# LargeDummyDevice register map
File version: 1.0
Registers are 32-bit, read-write, no defined reset value unless marked. A register's access mark holds for its fields unless they carry their own. Offsets are from the block's base; [hi:lo] are bit positions.

## PERIPHERAL_41
Base 0x40028000
0x04 REG_1 — Register 1
  [35:31] FIELD_29, [32:30] FIELD_13, [32:29] FIELD_31, [29:28] FIELD_12, [29:28] FIELD_23, [31:27] FIELD_22, [26:25] FIELD_4, [28:25] FIELD_28, [27:23] FIELD_15, [22] FIELD_21, [24:21] FIELD_6, [23:21] FIELD_10, [21] FIELD_25, [18:16] FIELD_5, [16] FIELD_8, [17:16] FIELD_9, [18:16] FIELD_16, [19:15] FIELD_1, [16:14] FIELD_7, [16:13] FIELD_3, [15:13] FIELD_18, [14:13] FIELD_20, [13] FIELD_24, [16:12] FIELD_14, [13:12] FIELD_17, [9:8] FIELD_26, [9:8] FIELD_30, [11:8] FIELD_32, [6:3] FIELD_2, [5:3] FIELD_19, [4:0] FIELD_11, [4:0] FIELD_27

## PERIPHERAL_48
Base 0x4002F000
0x04 REG_1 — Register 1
  [34:30] FIELD_16, [30:28] FIELD_18, [29:27] FIELD_12, [31:27] FIELD_20, [27:26] FIELD_28, [24] FIELD_27, [24:23] FIELD_24, [24:22] FIELD_6, [26:22] FIELD_19, [23:21] FIELD_4, [20] FIELD_3, [22:20] FIELD_13, [19:17] FIELD_7, [20:17] FIELD_14, [19:17] FIELD_15, [20:16] FIELD_21, [16:13] FIELD_10, [17:13] FIELD_11, [15:12] FIELD_25, [15:11] FIELD_2, [12:11] FIELD_22, [13:11] FIELD_23, [12:9] FIELD_17, [10:8] FIELD_26, [6:3] FIELD_1, [6:2] FIELD_8, [5:1] FIELD_5, [5:1] FIELD_9

## PERIPHERAL_52
Base 0x40033000
0x04 REG_1 — Register 1
  [33:30] FIELD_8, [33:29] FIELD_6, [33:29] FIELD_19, [32:28] FIELD_12, [27:24] FIELD_20, [26:23] FIELD_14, [25:22] FIELD_5, [25:22] FIELD_13, [23:22] FIELD_15, [24:20] FIELD_3, [19:17] FIELD_11, [16] FIELD_9, [18:15] FIELD_7, [16:12] FIELD_4, [12] FIELD_18, [13:9] FIELD_17, [12:8] FIELD_1, [8] FIELD_16, [5] FIELD_21, [8:4] FIELD_2, [4:1] FIELD_10
0x08 REG_2 — Register 2
  [31] FIELD_12, [34:31] FIELD_16, [32:29] FIELD_10, [29:28] FIELD_3, [27:23] FIELD_13, [25:23] FIELD_15, [23:19] FIELD_9, [22:18] FIELD_19, [19:15] FIELD_2, [14:12] FIELD_5, [13:12] FIELD_14, [10] FIELD_17, [10:9] FIELD_18, [11:7] FIELD_8, [6] FIELD_1, [5] FIELD_11, [2] FIELD_7, [1] FIELD_6, [0] FIELD_4
0x0C REG_3 — Register 3
  [33:31] FIELD_8, [35:31] FIELD_17, [31:30] FIELD_14, [27] FIELD_18, [28:26] FIELD_19, [24] FIELD_21, [26:22] FIELD_26, [21] FIELD_7, [23:21] FIELD_16, [19] FIELD_22, [21:18] FIELD_20, [16:15] FIELD_9, [17:15] FIELD_11, [18:14] FIELD_24, [13] FIELD_15, [13:12] FIELD_3, [12] FIELD_23, [10] FIELD_5, [11:8] FIELD_10, [8] FIELD_12, [10:8] FIELD_13, [8:5] FIELD_4, [3:2] FIELD_1, [2] FIELD_2, [4:1] FIELD_6, [0] FIELD_25
0x10 REG_4 — Register 4
  [8:7] FIELD_1
0x14 REG_5 — Register 5
  [32:31] FIELD_6, [33:30] FIELD_9, [28] FIELD_12, [31:27] FIELD_1, [28:26] FIELD_4, [25:23] FIELD_11, [23:20] FIELD_3, [14] FIELD_10, [17:14] FIELD_14, [16:14] FIELD_15, [12:10] FIELD_2, [13:9] FIELD_13, [4] FIELD_5, [5:2] FIELD_8, [1] FIELD_7

## PERIPHERAL_55
Base 0x40036000
0x04 REG_1 — Register 1
  [32:31] FIELD_7, [30] FIELD_9, [29:25] FIELD_2, [26:22] FIELD_3, [22] FIELD_11, [22:19] FIELD_6, [18:15] FIELD_4, [10:7] FIELD_5, [6:3] FIELD_1, [4:3] FIELD_8, [3:1] FIELD_10
0x08 REG_2 — Register 2
  [30:26] FIELD_9, [26] FIELD_22, [28:25] FIELD_4, [28:24] FIELD_18, [24:22] FIELD_1, [24:21] FIELD_5, [21:20] FIELD_11, [24:20] FIELD_20, [20] FIELD_23, [22:19] FIELD_13, [23:19] FIELD_19, [23:19] FIELD_25, [18] FIELD_14, [18:15] FIELD_16, [16:12] FIELD_12, [8] FIELD_7, [9:7] FIELD_15, [7:6] FIELD_2, [7:5] FIELD_3, [7:3] FIELD_6, [6:3] FIELD_21, [4:3] FIELD_24, [3:2] FIELD_17, [1] FIELD_8, [2:0] FIELD_10
0x0C REG_3 — Register 3
  [11:7] FIELD_1
0x10 REG_4 — Register 4
  [31:28] FIELD_7, [29:27] FIELD_10, [26] FIELD_11, [27:23] FIELD_5, [20] FIELD_3, [19] FIELD_8, [15:11] FIELD_6, [8:5] FIELD_2, [5:4] FIELD_9, [7:3] FIELD_1, [1] FIELD_4
0x14 REG_5 — Register 5
  [30] FIELD_3, [28:24] FIELD_2, [20:18] FIELD_4, [18:17] FIELD_5, [11:7] FIELD_1
0x18 REG_6 — Register 6
  [34:31] FIELD_4, [30] FIELD_5, [30:29] FIELD_6, [29:28] FIELD_7, [27] FIELD_1, [25:22] FIELD_3, [16:13] FIELD_2, [12:10] FIELD_9, [4:1] FIELD_8
0x1C REG_7 — Register 7
  [31] FIELD_1, [34:31] FIELD_3, [32:31] FIELD_13, [27:23] FIELD_6, [25:23] FIELD_18, [22:21] FIELD_22, [24:20] FIELD_2, [24:20] FIELD_14, [19] FIELD_5, [19:16] FIELD_7, [16:13] FIELD_11, [16:12] FIELD_9, [14:11] FIELD_10, [10:9] FIELD_17, [6:5] FIELD_12, [8:5] FIELD_16, [4:3] FIELD_20, [2] FIELD_15, [4:2] FIELD_19, [1] FIELD_8, [4:1] FIELD_21, [4:0] FIELD_4
0x20 REG_8 — Register 8
  [31:27] FIELD_18, [28:25] FIELD_3, [24:22] FIELD_17, [22:21] FIELD_16, [20:18] FIELD_10, [18] FIELD_11, [19:18] FIELD_14, [21:17] FIELD_12, [17:16] FIELD_7, [17:14] FIELD_8, [12] FIELD_1, [16:12] FIELD_4, [9] FIELD_6, [8:6] FIELD_9, [6:5] FIELD_15, [9:5] FIELD_19, [7:3] FIELD_5, [4:2] FIELD_2, [4:1] FIELD_13
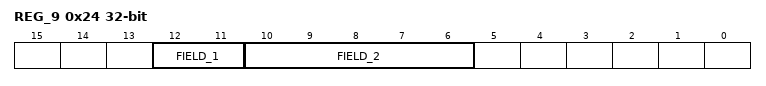
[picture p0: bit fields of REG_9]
0x24 REG_9 — Register 9
  [12:11] FIELD_1, [10:6] FIELD_2
0x28 REG_10 — Register 10
  [32:29] FIELD_15, [28] FIELD_1, [27] FIELD_5, [25:22] FIELD_3, [19] FIELD_9, [16:15] FIELD_8, [17:14] FIELD_14, [16:12] FIELD_2, [13:9] FIELD_6, [13:9] FIELD_16, [9:8] FIELD_10, [6:3] FIELD_4, [4:3] FIELD_11, [4:3] FIELD_13, [2:1] FIELD_12, [2:0] FIELD_7
0x2C REG_11 — Register 11
  [32:31] FIELD_2, [32:31] FIELD_15, [31:30] FIELD_12, [32:30] FIELD_21, [31:28] FIELD_13, [28] FIELD_27, [27] FIELD_9, [27] FIELD_11, [31:27] FIELD_16, [27] FIELD_18, [28:26] FIELD_17, [25] FIELD_8, [25:24] FIELD_7, [25:24] FIELD_23, [23:21] FIELD_14, [18] FIELD_30, [21:17] FIELD_5, [21:17] FIELD_26, [21:17] FIELD_31, [16] FIELD_19, [17:13] FIELD_10, [16:13] FIELD_20, [14:13] FIELD_28, [15:12] FIELD_24, [16:12] FIELD_25, [11:9] FIELD_6, [10:9] FIELD_32, [9:8] FIELD_1, [9:8] FIELD_29, [7] FIELD_3, [7] FIELD_4, [4] FIELD_22
